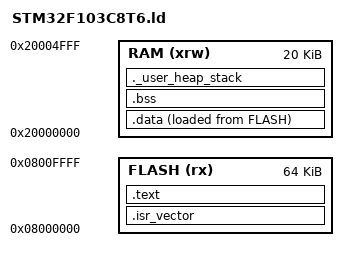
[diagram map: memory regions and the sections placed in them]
ENTRY(Reset_Handler)

_estack = ORIGIN(RAM) + LENGTH(RAM);

_Min_Heap_Size = 0;
_Min_Stack_Size = 0x400;

MEMORY
{
    RAM  (xrw) : ORIGIN = 0x20000000, LENGTH = 20K
    FLASH (rx) : ORIGIN = 0x08000000, LENGTH = 64K
}

SECTIONS
{
    .isr_vector :
    {
        . = ALIGN(4);
        KEEP(*(.isr_vector))
        . = ALIGN(4);
    } > FLASH

    .text :
    {
        . = ALIGN(4);
        *(.text)
        *(.text*)
        *(.rodata)
        *(.rodata*)
        *(.glue_7)
        *(.glue_7t)
        *(.eh_frame)

        KEEP (*(.init))
        KEEP (*(.fini))

        . = ALIGN(4);
        _etext = .;
    } > FLASH

    _sidata = LOADADDR(.data);

    .data :
    {
        . = ALIGN(4);
        _sdata = .;
        *(.data)
        *(.data*)

        . = ALIGN(4);
        _edata = .;
    } > RAM AT > FLASH

    . = ALIGN(4);
    .bss :
    {
        _sbss = .;
        __bss_start__ = _sbss;
        *(.bss)
        *(.bss*)
        *(COMMON)

        . = ALIGN(4);
        _ebss = .;
        __bss_end__ = _ebss;
    } > RAM

    PROVIDE(end = .);
    PROVIDE(_end = .);

    ._user_heap_stack :
    {
        . = ALIGN(8);
        . = . + _Min_Heap_Size;
        . = . + _Min_Stack_Size;
        . = ALIGN(8);
    } > RAM

    /DISCARD/ :
    {
        libc.a ( * )
        libm.a ( * )
        libgcc.a ( * )
    }
}
